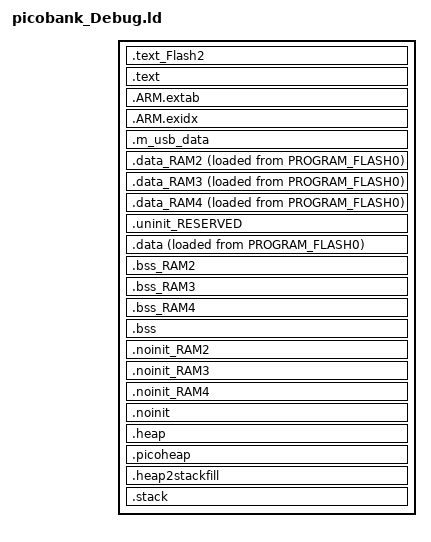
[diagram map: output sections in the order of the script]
/*
 * GENERATED FILE - DO NOT EDIT
 * Copyright 2008-2013 Code Red Technologies Ltd,
 * Copyright 2013-2026 NXP
 * SPDX-License-Identifier: BSD-3-Clause
 * Generated linker script file for MCXN947
 * Created from linkscript.ldt by FMCreateLinkLibraries
 * Using Freemarker v2.3.30
 * MCUXpresso IDE v25.6 [Build 136] [2025-06-27] on Feb 9, 2026, 5:10:37 PM
 */

INCLUDE "picobank_Debug_library.ld"
INCLUDE "picobank_Debug_memory.ld"

ENTRY(ResetISR)

SECTIONS
{
     .text_Flash2 : ALIGN(4)
    {
       FILL(0xff)
        *(.text_Flash2) /* for compatibility with previous releases */
        *(.text_PROGRAM_FLASH1) /* for compatibility with previous releases */
        *(.text.$Flash2)
        *(.text.$PROGRAM_FLASH1)
        *(.text_Flash2.*) /* for compatibility with previous releases */
        *(.text_PROGRAM_FLASH1.*) /* for compatibility with previous releases */
        *(.text.$Flash2.*)
        *(.text.$PROGRAM_FLASH1.*)
        *(.rodata.$Flash2)
        *(.rodata.$PROGRAM_FLASH1)
        *(.rodata.$Flash2.*)
        *(.rodata.$PROGRAM_FLASH1.*)            } > PROGRAM_FLASH1

    /* MAIN TEXT SECTION */
    .text : ALIGN(4)
    {
        FILL(0xff)
        __vectors_start__ = ABSOLUTE(.) ;
        KEEP(*(.isr_vector))
        /* Global Section Table */
        . = ALIGN(4) ;
        __section_table_start = .;
        __data_section_table = .;
        LONG(LOADADDR(.data));
        LONG(    ADDR(.data));
        LONG(  SIZEOF(.data));
        LONG(LOADADDR(.data_RAM2));
        LONG(    ADDR(.data_RAM2));
        LONG(  SIZEOF(.data_RAM2));
        LONG(LOADADDR(.data_RAM3));
        LONG(    ADDR(.data_RAM3));
        LONG(  SIZEOF(.data_RAM3));
        LONG(LOADADDR(.data_RAM4));
        LONG(    ADDR(.data_RAM4));
        LONG(  SIZEOF(.data_RAM4));
        __data_section_table_end = .;
        __bss_section_table = .;
        LONG(    ADDR(.bss));
        LONG(  SIZEOF(.bss));
        LONG(    ADDR(.bss_RAM2));
        LONG(  SIZEOF(.bss_RAM2));
        LONG(    ADDR(.bss_RAM3));
        LONG(  SIZEOF(.bss_RAM3));
        LONG(    ADDR(.bss_RAM4));
        LONG(  SIZEOF(.bss_RAM4));
        __bss_section_table_end = .;
        __section_table_end = . ;
        /* End of Global Section Table */

        *(.after_vectors*)

       *(.text*)
       *(.rodata .rodata.* .constdata .constdata.*)
       . = ALIGN(4);
    } > PROGRAM_FLASH0
    /*
     * for exception handling/unwind - some Newlib functions (in common
     * with C++ and STDC++) use this.
     */
    .ARM.extab : ALIGN(4)
    {
        *(.ARM.extab* .gnu.linkonce.armextab.*)
    } > PROGRAM_FLASH0

    .ARM.exidx : ALIGN(4)
    {
        __exidx_start = .;
        *(.ARM.exidx* .gnu.linkonce.armexidx.*)
        __exidx_end = .;
    } > PROGRAM_FLASH0
 
    _etext = .;
        
 
    /* USB_RAM */
    .m_usb_data (NOLOAD) :
    {
        *(m_usb_global)
    } > USB_RAM AT> USB_RAM
    /* DATA section for SRAMX */

    .data_RAM2 : ALIGN(4)
    {
        FILL(0xff)
        PROVIDE(__start_data_RAM2 = .) ;
        PROVIDE(__start_data_SRAMX = .) ;
        *(.ramfunc.$RAM2)
        *(.ramfunc.$SRAMX)
        *(.data.$RAM2)
        *(.data.$SRAMX)
        *(.data.$RAM2.*)
        *(.data.$SRAMX.*)
        . = ALIGN(4) ;
        PROVIDE(__end_data_RAM2 = .) ;
        PROVIDE(__end_data_SRAMX = .) ;
     } > SRAMX AT>PROGRAM_FLASH0

    /* DATA section for SRAMH */

    .data_RAM3 : ALIGN(4)
    {
        FILL(0xff)
        PROVIDE(__start_data_RAM3 = .) ;
        PROVIDE(__start_data_SRAMH = .) ;
        *(.ramfunc.$RAM3)
        *(.ramfunc.$SRAMH)
        *(.data.$RAM3)
        *(.data.$SRAMH)
        *(.data.$RAM3.*)
        *(.data.$SRAMH.*)
        . = ALIGN(4) ;
        PROVIDE(__end_data_RAM3 = .) ;
        PROVIDE(__end_data_SRAMH = .) ;
     } > SRAMH AT>PROGRAM_FLASH0

    /* DATA section for USB_RAM */

    .data_RAM4 : ALIGN(4)
    {
        FILL(0xff)
        PROVIDE(__start_data_RAM4 = .) ;
        PROVIDE(__start_data_USB_RAM = .) ;
        *(.ramfunc.$RAM4)
        *(.ramfunc.$USB_RAM)
        *(.data.$RAM4)
        *(.data.$USB_RAM)
        *(.data.$RAM4.*)
        *(.data.$USB_RAM.*)
        . = ALIGN(4) ;
        PROVIDE(__end_data_RAM4 = .) ;
        PROVIDE(__end_data_USB_RAM = .) ;
     } > USB_RAM AT>PROGRAM_FLASH0

    /* MAIN DATA SECTION */
    .uninit_RESERVED (NOLOAD) : ALIGN(4)
    {
        _start_uninit_RESERVED = .;
        KEEP(*(.bss.$RESERVED*))
       . = ALIGN(4) ;
        _end_uninit_RESERVED = .;
    } > SRAM AT> SRAM

    /* Main DATA section (SRAM) */
    .data : ALIGN(4)
    {
       FILL(0xff)
       _data = . ;
       PROVIDE(__start_data_RAM = .) ;
       PROVIDE(__start_data_SRAM = .) ;
       *(vtable)
       *(.ramfunc*)
       KEEP(*(CodeQuickAccess))
       KEEP(*(DataQuickAccess))
       *(RamFunction)
       *(.data*)
       . = ALIGN(4) ;
       _edata = . ;
       PROVIDE(__end_data_RAM = .) ;
       PROVIDE(__end_data_SRAM = .) ;
    } > SRAM AT>PROGRAM_FLASH0

    /* BSS section for SRAMX */
    .bss_RAM2 (NOLOAD) : ALIGN(4)
    {
       PROVIDE(__start_bss_RAM2 = .) ;
       PROVIDE(__start_bss_SRAMX = .) ;
       *(.bss.$RAM2)
       *(.bss.$SRAMX)
       *(.bss.$RAM2.*)
       *(.bss.$SRAMX.*)
       . = ALIGN (. != 0 ? 4 : 1) ; /* avoid empty segment */
       PROVIDE(__end_bss_RAM2 = .) ;
       PROVIDE(__end_bss_SRAMX = .) ;
    } > SRAMX AT> SRAMX

    /* BSS section for SRAMH */
    .bss_RAM3 (NOLOAD) : ALIGN(4)
    {
       PROVIDE(__start_bss_RAM3 = .) ;
       PROVIDE(__start_bss_SRAMH = .) ;
       *(.bss.$RAM3)
       *(.bss.$SRAMH)
       *(.bss.$RAM3.*)
       *(.bss.$SRAMH.*)
       . = ALIGN (. != 0 ? 4 : 1) ; /* avoid empty segment */
       PROVIDE(__end_bss_RAM3 = .) ;
       PROVIDE(__end_bss_SRAMH = .) ;
    } > SRAMH AT> SRAMH

    /* BSS section for USB_RAM */
    .bss_RAM4 (NOLOAD) : ALIGN(4)
    {
       PROVIDE(__start_bss_RAM4 = .) ;
       PROVIDE(__start_bss_USB_RAM = .) ;
       *(.bss.$RAM4)
       *(.bss.$USB_RAM)
       *(.bss.$RAM4.*)
       *(.bss.$USB_RAM.*)
       . = ALIGN (. != 0 ? 4 : 1) ; /* avoid empty segment */
       PROVIDE(__end_bss_RAM4 = .) ;
       PROVIDE(__end_bss_USB_RAM = .) ;
    } > USB_RAM AT> USB_RAM

    /* MAIN BSS SECTION */
    .bss (NOLOAD) : ALIGN(4)
    {
        _bss = .;
        PROVIDE(__start_bss_RAM = .) ;
        PROVIDE(__start_bss_SRAM = .) ;
        *(.bss*)
        *(COMMON)
        . = ALIGN(4) ;
        _ebss = .;
        PROVIDE(__end_bss_RAM = .) ;
        PROVIDE(__end_bss_SRAM = .) ;
        PROVIDE(end = .);
    } > SRAM AT> SRAM

    /* NOINIT section for SRAMX */
    .noinit_RAM2 (NOLOAD) : ALIGN(4)
    {
       PROVIDE(__start_noinit_RAM2 = .) ;
       PROVIDE(__start_noinit_SRAMX = .) ;
       *(.noinit.$RAM2)
       *(.noinit.$SRAMX)
       *(.noinit.$RAM2.*)
       *(.noinit.$SRAMX.*)
       . = ALIGN(4) ;
       PROVIDE(__end_noinit_RAM2 = .) ;
       PROVIDE(__end_noinit_SRAMX = .) ;
    } > SRAMX AT> SRAMX

    /* NOINIT section for SRAMH */
    .noinit_RAM3 (NOLOAD) : ALIGN(4)
    {
       PROVIDE(__start_noinit_RAM3 = .) ;
       PROVIDE(__start_noinit_SRAMH = .) ;
       *(.noinit.$RAM3)
       *(.noinit.$SRAMH)
       *(.noinit.$RAM3.*)
       *(.noinit.$SRAMH.*)
       . = ALIGN(4) ;
       PROVIDE(__end_noinit_RAM3 = .) ;
       PROVIDE(__end_noinit_SRAMH = .) ;
    } > SRAMH AT> SRAMH

    /* NOINIT section for USB_RAM */
    .noinit_RAM4 (NOLOAD) : ALIGN(4)
    {
       PROVIDE(__start_noinit_RAM4 = .) ;
       PROVIDE(__start_noinit_USB_RAM = .) ;
       *(.noinit.$RAM4)
       *(.noinit.$USB_RAM)
       *(.noinit.$RAM4.*)
       *(.noinit.$USB_RAM.*)
       . = ALIGN(4) ;
       PROVIDE(__end_noinit_RAM4 = .) ;
       PROVIDE(__end_noinit_USB_RAM = .) ;
    } > USB_RAM AT> USB_RAM

    /* DEFAULT NOINIT SECTION */
    .noinit (NOLOAD): ALIGN(4)
    {
        _noinit = .;
        PROVIDE(__start_noinit_RAM = .) ;
        PROVIDE(__start_noinit_SRAM = .) ;
        *(.noinit*)
         . = ALIGN(4) ;
        _end_noinit = .;
       PROVIDE(__end_noinit_RAM = .) ;
       PROVIDE(__end_noinit_SRAM = .) ;        
    } > SRAM AT> SRAM

    /* Reserve and place Heap within memory map */
    _HeapSize = 0x20000;
    .heap (NOLOAD) :  ALIGN(4)
    {
        _pvHeapStart = .;
        . += _HeapSize;
        . = ALIGN(4);
        _pvHeapLimit = .;
    } > SRAM

    _PicoHeapSize = 0x30000;
    .picoheap (NOLOAD) : ALIGN(256)
    {
    	_pvPicoHeapStart = .;
    	. += _PicoHeapSize;
    	. = ALIGN(4);
    	_pvPicoHeapLimit = .;
    } > SRAM
    
     _StackSize = 0x1000;
    .heap2stackfill (NOLOAD) : 
    {
        . += _StackSize;
    } > SRAM

    .stack ORIGIN(SRAM) + LENGTH(SRAM) - _StackSize - 0 (NOLOAD) :  ALIGN(4)
    {
        _vStackBase = .;
        . = ALIGN(4);
        _vStackTop = . + _StackSize;
    } > SRAM

    /* Provide basic symbols giving location and size of main text
     * block, including initial values of RW data sections. Note that
     * these will need extending to give a complete picture with
     * complex images (e.g multiple Flash banks).
     */
    _image_start = LOADADDR(.text);
    _image_end = LOADADDR(.data) + SIZEOF(.data);
    _image_size = _image_end - _image_start;
}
